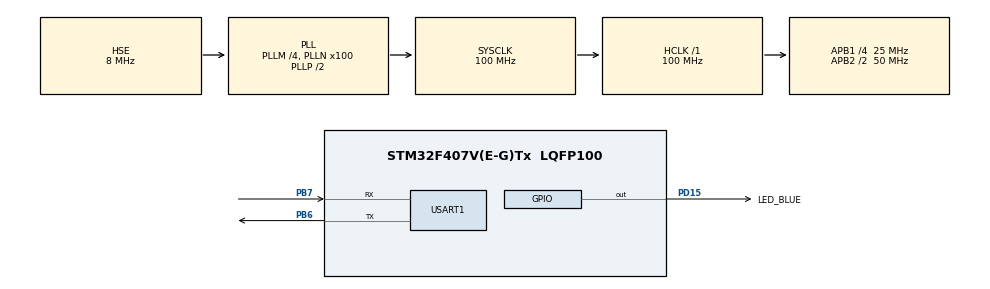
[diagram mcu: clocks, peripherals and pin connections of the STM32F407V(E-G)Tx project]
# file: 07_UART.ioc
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Mcu.Family=STM32F4
RCC.PLLSourceVirtual=RCC_PLLSOURCE_HSE
TIM10.Prescaler=9999
PH0-OSC_IN.Signal=RCC_OSC_IN
RCC.CortexFreq_Value=100000000
PD15.GPIO_Label=LED_BLUE
TIM10.ClockDivision=TIM_CLOCKDIVISION_DIV2
RCC.APB1CLKDivider=RCC_HCLK_DIV4
RCC.SYSCLKSource=RCC_SYSCLKSOURCE_PLLCLK
ProjectManager.StackSize=0x400
ProjectManager.TargetToolchain=STM32CubeIDE
RCC.HCLKFreq_Value=100000000
RCC.APB2TimFreq_Value=100000000
PB6.Signal=USART1_TX
VP_TIM10_VS_ClockSourceINT.Mode=Enable_Timer
PB6.Mode=Asynchronous
RCC.LSE_VALUE=32768
RCC.AHBFreq_Value=100000000
PH0-OSC_IN.Mode=HSE-External-Oscillator
RCC.HSE_VALUE=8000000
board=custom
RCC.VCOOutputFreq_Value=200000000
TIM10.Period=9999
RCC.APB2Freq_Value=50000000
PH1-OSC_OUT.Signal=RCC_OSC_OUT
PB7.Signal=USART1_RX
Mcu.Name=STM32F407V(E-G)Tx
PH1-OSC_OUT.Mode=HSE-External-Oscillator
RCC.48MHZClocksFreq_Value=50000000
RCC.SYSCLKFreq_VALUE=100000000
Mcu.Package=LQFP100
USART1.VirtualMode=VM_ASYNC
PB7.Mode=Asynchronous
ProjectManager.HeapSize=0x200
NVIC.TIM1_UP_TIM10_IRQn=true\:0\:0\:false\:false\:true\:true\:true
RCC.HSI_VALUE=16000000
NVIC.PriorityGroup=NVIC_PRIORITYGROUP_4
RCC.APB2CLKDivider=RCC_HCLK_DIV2
RCC.PLLM=4
RCC.PLLN=100
RCC.APB1TimFreq_Value=50000000
NVIC.USART1_IRQn=true\:0\:0\:false\:false\:true\:true\:true
RCC.APB1Freq_Value=25000000
PD15.Signal=GPIO_Output

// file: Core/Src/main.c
/* USER CODE BEGIN Header */
/**
  ******************************************************************************
  * @file           : main.c
  * @brief          : Main program body
  ******************************************************************************
  * @attention
  *
  * <h2><center>&copy; Copyright (c) 2021 STMicroelectronics.
  * All rights reserved.</center></h2>
  *
  * This software component is licensed by ST under BSD 3-Clause license,
  * the "License"; You may not use this file except in compliance with the
  * License. You may obtain a copy of the License at:
  *                        opensource.org/licenses/BSD-3-Clause
  *
  ******************************************************************************
  */
/* USER CODE END Header */
#include "main.h"

TIM_HandleTypeDef htim10;

UART_HandleTypeDef huart1;

void SystemClock_Config(void);
static void MX_GPIO_Init(void);
static void MX_TIM10_Init(void);
static void MX_USART1_UART_Init(void);
/* USER CODE BEGIN PFP */
void HAL_TIM_PeriodElapsedCallback(TIM_HandleTypeDef *htim){

	static uint16_t cnt = 0; 	//Licznik wysyłanych wiadmości
	uint8_t data[50];	 //Talica przechowująca wysłaną wiadomość
	uint16_t size = 0;	//Rozmiar wysłanej wiadomości

	++cnt;		//Zwiększenie licznika wysłnych wiadomości
	size = sprintf (data, "Liczba wysłanych wiadomości: %d. \n\r", cnt);	//Stworzenie wiadomości do wysłania oraz przypisanie ilości wysłanych znaków do zmiennej size

HAL_UART_Transmit_IT(&huart1, data, size);
HAL_GPIO_TogglePin(LED_BLUE_GPIO_Port, LED_BLUE_Pin);
}
/* USER CODE END PFP */

int main(void)
{

  /* MCU Configuration--------------------------------------------------------*/

  /* Reset of all peripherals, Initializes the Flash interface and the Systick. */
  HAL_Init();

  /* Configure the system clock */
  SystemClock_Config();

  /* Initialize all configured peripherals */
  MX_GPIO_Init();
  MX_TIM10_Init();
  MX_USART1_UART_Init();
  /* USER CODE BEGIN 2 */
  HAL_TIM_Base_Start_IT(&htim10);
  /* USER CODE END 2 */

  /* Infinite loop */
  while (1)
  {

  }
}

void SystemClock_Config(void)
{
  RCC_OscInitTypeDef RCC_OscInitStruct = {0};
  RCC_ClkInitTypeDef RCC_ClkInitStruct = {0};

  /** Configure the main internal regulator output voltage
  */
  __HAL_RCC_PWR_CLK_ENABLE();
  __HAL_PWR_VOLTAGESCALING_CONFIG(PWR_REGULATOR_VOLTAGE_SCALE1);
  /** Initializes the RCC Oscillators according to the specified parameters
  * in the RCC_OscInitTypeDef structure.
  */
  RCC_OscInitStruct.OscillatorType = RCC_OSCILLATORTYPE_HSE;
  RCC_OscInitStruct.HSEState = RCC_HSE_ON;
  RCC_OscInitStruct.PLL.PLLState = RCC_PLL_ON;
  RCC_OscInitStruct.PLL.PLLSource = RCC_PLLSOURCE_HSE;
  RCC_OscInitStruct.PLL.PLLM = 4;
  RCC_OscInitStruct.PLL.PLLN = 100;
  RCC_OscInitStruct.PLL.PLLP = RCC_PLLP_DIV2;
  RCC_OscInitStruct.PLL.PLLQ = 4;
  if (HAL_RCC_OscConfig(&RCC_OscInitStruct) != HAL_OK)
  {
    Error_Handler();
  }
  /** Initializes the CPU, AHB and APB buses clocks
  */
  RCC_ClkInitStruct.ClockType = RCC_CLOCKTYPE_HCLK|RCC_CLOCKTYPE_SYSCLK
                              |RCC_CLOCKTYPE_PCLK1|RCC_CLOCKTYPE_PCLK2;
  RCC_ClkInitStruct.SYSCLKSource = RCC_SYSCLKSOURCE_PLLCLK;
  RCC_ClkInitStruct.AHBCLKDivider = RCC_SYSCLK_DIV1;
  RCC_ClkInitStruct.APB1CLKDivider = RCC_HCLK_DIV4;
  RCC_ClkInitStruct.APB2CLKDivider = RCC_HCLK_DIV2;

  if (HAL_RCC_ClockConfig(&RCC_ClkInitStruct, FLASH_LATENCY_3) != HAL_OK)
  {
    Error_Handler();
  }
}

static void MX_TIM10_Init(void)
{

  htim10.Instance = TIM10;
  htim10.Init.Prescaler = 9999;
  htim10.Init.CounterMode = TIM_COUNTERMODE_UP;
  htim10.Init.Period = 9999;
  htim10.Init.ClockDivision = TIM_CLOCKDIVISION_DIV2;
  htim10.Init.AutoReloadPreload = TIM_AUTORELOAD_PRELOAD_DISABLE;
  if (HAL_TIM_Base_Init(&htim10) != HAL_OK)
  {
    Error_Handler();
  }

}

static void MX_USART1_UART_Init(void)
{

  huart1.Instance = USART1;
  huart1.Init.BaudRate = 115200;
  huart1.Init.WordLength = UART_WORDLENGTH_8B;
  huart1.Init.StopBits = UART_STOPBITS_1;
  huart1.Init.Parity = UART_PARITY_NONE;
  huart1.Init.Mode = UART_MODE_TX_RX;
  huart1.Init.HwFlowCtl = UART_HWCONTROL_NONE;
  huart1.Init.OverSampling = UART_OVERSAMPLING_16;
  if (HAL_UART_Init(&huart1) != HAL_OK)
  {
    Error_Handler();
  }

}

static void MX_GPIO_Init(void)
{
  GPIO_InitTypeDef GPIO_InitStruct = {0};

  /* GPIO Ports Clock Enable */
  __HAL_RCC_GPIOH_CLK_ENABLE();
  __HAL_RCC_GPIOD_CLK_ENABLE();
  __HAL_RCC_GPIOB_CLK_ENABLE();

  /*Configure GPIO pin Output Level */
  HAL_GPIO_WritePin(LED_BLUE_GPIO_Port, LED_BLUE_Pin, GPIO_PIN_RESET);

  /*Configure GPIO pin : LED_BLUE_Pin */
  GPIO_InitStruct.Pin = LED_BLUE_Pin;
  GPIO_InitStruct.Mode = GPIO_MODE_OUTPUT_PP;
  GPIO_InitStruct.Pull = GPIO_NOPULL;
  GPIO_InitStruct.Speed = GPIO_SPEED_FREQ_LOW;
  HAL_GPIO_Init(LED_BLUE_GPIO_Port, &GPIO_InitStruct);

}

void Error_Handler(void)
{
  __disable_irq();
  while (1)
  {
  }
}

/************************ (C) COPYRIGHT STMicroelectronics *****END OF FILE****/
